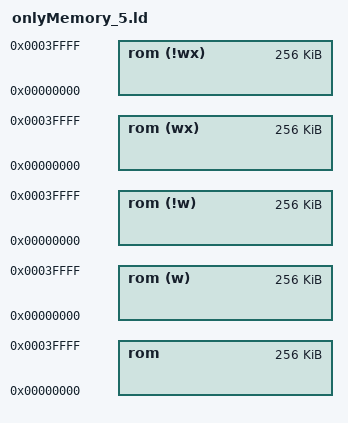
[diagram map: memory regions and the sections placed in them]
MEMORY 
{
    rom   : ORIGIN = 0, LENGTH = 256K
    rom (w)  : ORIGIN = 0, LENGTH = 256K
    rom (!w)  : ORIGIN = 0, LENGTH = 256K
    rom (wx)  : ORIGIN = 0, LENGTH = 256K
    rom (!wx)  : ORIGIN = 0, LENGTH = 256K
}
